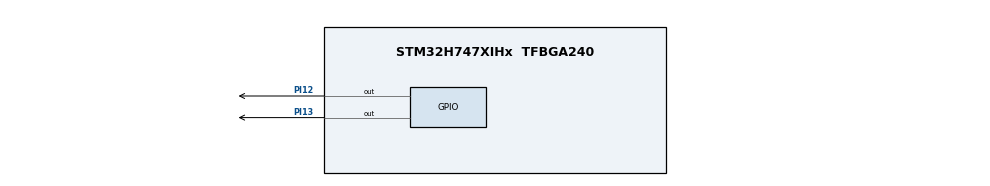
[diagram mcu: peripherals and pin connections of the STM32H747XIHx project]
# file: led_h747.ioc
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CORTEX_M7.CPU_DCache=Enabled
CORTEX_M7.CPU_ICache=Enabled
CortexM4.IPs=BDMA,DMA,FATFS_M4\:I,FREERTOS_M4\:I,IWDG2\:I,MDMA,NVIC2\:I,RCC,USB_DEVICE_M4\:I,USB_HOST_M4\:I,WWDG2\:I,USART1,USB_OTG_HS\:I,SPI2\:I,ADC3\:I,FMC\:I,QUADSPI\:I,SAI1\:I,ETH\:I,SPI5\:I,TIM8\:I,UART8\:I,DCMI\:I,RTC\:I,SDMMC1\:I,SPDIFRX1\:I,HDMI_CEC\:I,TIM13\:I,TIM3\:I,DEBUG,PDM2PCM_M4\:I,PWR,RESMGR_UTILITY,SYS_M4\:I,CORTEX_M4\:I,OPENAMP_M4\:I,VREFBUF,GPIO
CortexM4.Pins=PI13
CortexM7.IPs=BDMA\:I,DMA\:I,FATFS_M7\:I,FREERTOS_M7\:I,IWDG1\:I,MDMA\:I,NVIC1\:I,RCC\:I,USB_DEVICE_M7\:I,USB_HOST_M7\:I,WWDG1\:I,USART1\:I,CORTEX_M7\:I,DEBUG\:I,PDM2PCM_M7\:I,PWR\:I,RESMGR_UTILITY\:I,SYS\:I,OPENAMP_M7\:I,VREFBUF\:I,GPIO\:I
CortexM7.Pins=PI12
Mcu.Family=STM32H7
Mcu.Name=STM32H747XIHx
Mcu.Package=TFBGA240
NVIC1.PriorityGroup=NVIC_PRIORITYGROUP_4
NVIC2.PriorityGroup=NVIC_PRIORITYGROUP_4
PH0-OSC_IN\ (PH0).Mode=HSE-External-Oscillator
PH0-OSC_IN\ (PH0).PinAttribute=Free
PH0-OSC_IN\ (PH0).Signal=RCC_OSC_IN
PH1-OSC_OUT\ (PH1).Mode=HSE-External-Oscillator
PH1-OSC_OUT\ (PH1).PinAttribute=Free
PH1-OSC_OUT\ (PH1).Signal=RCC_OSC_OUT
PI12.PinAttribute=CortexM7
PI12.Signal=GPIO_Output
PI13.PinAttribute=CortexM4
PI13.Signal=GPIO_Output
ProjectManager.HeapSize=M4-0x200,M7-0x200
ProjectManager.StackSize=M4-0x400,M7-0x400
ProjectManager.TargetToolchain=STM32CubeIDE
RCC.ADCFreq_Value=75000000
RCC.APB1Freq_Value=100000000
RCC.APB2Freq_Value=100000000
RCC.APB3Freq_Value=100000000
RCC.APB4Freq_Value=100000000
RCC.CortexFreq_Value=400000000
RCC.D1PPRE=RCC_APB3_DIV2
RCC.D2PPRE1=RCC_APB1_DIV2
RCC.D2PPRE2=RCC_APB2_DIV2
RCC.D3PPRE=RCC_APB4_DIV2
RCC.DIVM1=5
RCC.DIVM2=2
RCC.DIVN1=160
RCC.DIVN2=12
RCC.DIVQ1=5
RCC.HCLKFreq_Value=200000000
RCC.HPRE=RCC_HCLK_DIV2
RCC.PLL2FRACN=0
RCC.PLL3FRACN=0
RCC.PLLFRACN=0
RCC.PLLSourceVirtual=RCC_PLLSOURCE_HSE
RCC.PWR_Regulator_Voltage_Scale=PWR_REGULATOR_VOLTAGE_SCALE1
RCC.SYSCLKFreq_VALUE=400000000
RCC.SYSCLKSource=RCC_SYSCLKSOURCE_PLLCLK
RCC.SupplySource=PWR_DIRECT_SMPS_SUPPLY
RCC.USBFreq_Value=160000000
VP_SYS_M4_VS_Systick.Mode=SysTick
board=STM32H747I-DISCO

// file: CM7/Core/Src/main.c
/* USER CODE BEGIN Header */
/**
  ******************************************************************************
  * @file           : main.c
  * @brief          : Main program body
  ******************************************************************************
  * @attention
  *
  * Copyright (c) 2024 STMicroelectronics.
  * All rights reserved.
  *
  * This software is licensed under terms that can be found in the LICENSE file
  * in the root directory of this software component.
  * If no LICENSE file comes with this software, it is provided AS-IS.
  *
  ******************************************************************************
  */
/* USER CODE END Header */
#include "main.h"

/* USER CODE BEGIN PD */

#ifndef HSEM_ID_0
#define HSEM_ID_0 (0U) /* HW semaphore 0*/
#endif

/* USER CODE END PD */

void SystemClock_Config(void);
static void MX_GPIO_Init(void);

int main(void)
{

/* USER CODE BEGIN Boot_Mode_Sequence_0 */
#if 0
  int32_t timeout;
/* USER CODE END Boot_Mode_Sequence_0 */

  /* Enable the CPU Cache */

  /* Enable I-Cache---------------------------------------------------------*/
  SCB_EnableICache();

  /* Enable D-Cache---------------------------------------------------------*/
  SCB_EnableDCache();

/* USER CODE BEGIN Boot_Mode_Sequence_1 */
  /* Wait until CPU2 boots and enters in stop mode or timeout*/
  timeout = 0xFFFF;
  while((__HAL_RCC_GET_FLAG(RCC_FLAG_D2CKRDY) != RESET) && (timeout-- > 0));
  if ( timeout < 0 )
  {
  Error_Handler();
  }
/* USER CODE END Boot_Mode_Sequence_1 */
  /* MCU Configuration--------------------------------------------------------*/

  /* Reset of all peripherals, Initializes the Flash interface and the Systick. */
  HAL_Init();

  /* Configure the system clock */
  SystemClock_Config();
/* USER CODE BEGIN Boot_Mode_Sequence_2 */
/* When system initialization is finished, Cortex-M7 will release Cortex-M4 by means of
HSEM notification */
/*HW semaphore Clock enable*/
__HAL_RCC_HSEM_CLK_ENABLE();
/*Take HSEM */
HAL_HSEM_FastTake(HSEM_ID_0);
/*Release HSEM in order to notify the CPU2(CM4)*/
HAL_HSEM_Release(HSEM_ID_0,0);
/* wait until CPU2 wakes up from stop mode */
timeout = 0xFFFF;
while((__HAL_RCC_GET_FLAG(RCC_FLAG_D2CKRDY) == RESET) && (timeout-- > 0));
if ( timeout < 0 )
{
Error_Handler();
}
#endif
/* USER CODE END Boot_Mode_Sequence_2 */

  /* USER CODE BEGIN SysInit */
HAL_Init();
SystemClock_Config();
  /* USER CODE END SysInit */

  /* Initialize all configured peripherals */
  MX_GPIO_Init();

  /* Infinite loop */
  while (1)
  {

    /* USER CODE BEGIN 3 */
	  HAL_GPIO_TogglePin(GPIOI, GPIO_PIN_12);
	  HAL_Delay(500);

	  HAL_GPIO_TogglePin(GPIOI, GPIO_PIN_14);
	  	  HAL_Delay(500);

	  	HAL_GPIO_TogglePin(GPIOI, GPIO_PIN_15);
	  		  HAL_Delay(500);
  }
  /* USER CODE END 3 */
}

void SystemClock_Config(void)
{
  RCC_OscInitTypeDef RCC_OscInitStruct = {0};
  RCC_ClkInitTypeDef RCC_ClkInitStruct = {0};

  /** Supply configuration update enable
  */
  HAL_PWREx_ConfigSupply(PWR_DIRECT_SMPS_SUPPLY);

  /** Configure the main internal regulator output voltage
  */
  __HAL_PWR_VOLTAGESCALING_CONFIG(PWR_REGULATOR_VOLTAGE_SCALE1);

  while(!__HAL_PWR_GET_FLAG(PWR_FLAG_VOSRDY)) {}

  /** Initializes the RCC Oscillators according to the specified parameters
  * in the RCC_OscInitTypeDef structure.
  */
  RCC_OscInitStruct.OscillatorType = RCC_OSCILLATORTYPE_HSE;
  RCC_OscInitStruct.HSEState = RCC_HSE_ON;
  RCC_OscInitStruct.PLL.PLLState = RCC_PLL_ON;
  RCC_OscInitStruct.PLL.PLLSource = RCC_PLLSOURCE_HSE;
  RCC_OscInitStruct.PLL.PLLM = 5;
  RCC_OscInitStruct.PLL.PLLN = 160;
  RCC_OscInitStruct.PLL.PLLP = 2;
  RCC_OscInitStruct.PLL.PLLQ = 5;
  RCC_OscInitStruct.PLL.PLLR = 2;
  RCC_OscInitStruct.PLL.PLLRGE = RCC_PLL1VCIRANGE_2;
  RCC_OscInitStruct.PLL.PLLVCOSEL = RCC_PLL1VCOWIDE;
  RCC_OscInitStruct.PLL.PLLFRACN = 0;
  if (HAL_RCC_OscConfig(&RCC_OscInitStruct) != HAL_OK)
  {
    Error_Handler();
  }

  /** Initializes the CPU, AHB and APB buses clocks
  */
  RCC_ClkInitStruct.ClockType = RCC_CLOCKTYPE_HCLK|RCC_CLOCKTYPE_SYSCLK
                              |RCC_CLOCKTYPE_PCLK1|RCC_CLOCKTYPE_PCLK2
                              |RCC_CLOCKTYPE_D3PCLK1|RCC_CLOCKTYPE_D1PCLK1;
  RCC_ClkInitStruct.SYSCLKSource = RCC_SYSCLKSOURCE_PLLCLK;
  RCC_ClkInitStruct.SYSCLKDivider = RCC_SYSCLK_DIV1;
  RCC_ClkInitStruct.AHBCLKDivider = RCC_HCLK_DIV2;
  RCC_ClkInitStruct.APB3CLKDivider = RCC_APB3_DIV2;
  RCC_ClkInitStruct.APB1CLKDivider = RCC_APB1_DIV2;
  RCC_ClkInitStruct.APB2CLKDivider = RCC_APB2_DIV2;
  RCC_ClkInitStruct.APB4CLKDivider = RCC_APB4_DIV2;

  if (HAL_RCC_ClockConfig(&RCC_ClkInitStruct, FLASH_LATENCY_2) != HAL_OK)
  {
    Error_Handler();
  }
}

static void MX_GPIO_Init(void)
{
  GPIO_InitTypeDef GPIO_InitStruct = {0};

  /* GPIO Ports Clock Enable */
  __HAL_RCC_GPIOI_CLK_ENABLE();

  /*Configure GPIO pin Output Level */
  HAL_GPIO_WritePin(GPIOI, GPIO_PIN_12, GPIO_PIN_RESET);

  /*Configure GPIO pin : PI12 */
  GPIO_InitStruct.Pin = GPIO_PIN_12;
  GPIO_InitStruct.Mode = GPIO_MODE_OUTPUT_PP;
  GPIO_InitStruct.Pull = GPIO_NOPULL;
  GPIO_InitStruct.Speed = GPIO_SPEED_FREQ_LOW;
  HAL_GPIO_Init(GPIOI, &GPIO_InitStruct);

}

void Error_Handler(void)
{
  __disable_irq();
  while (1)
  {
  }
}
